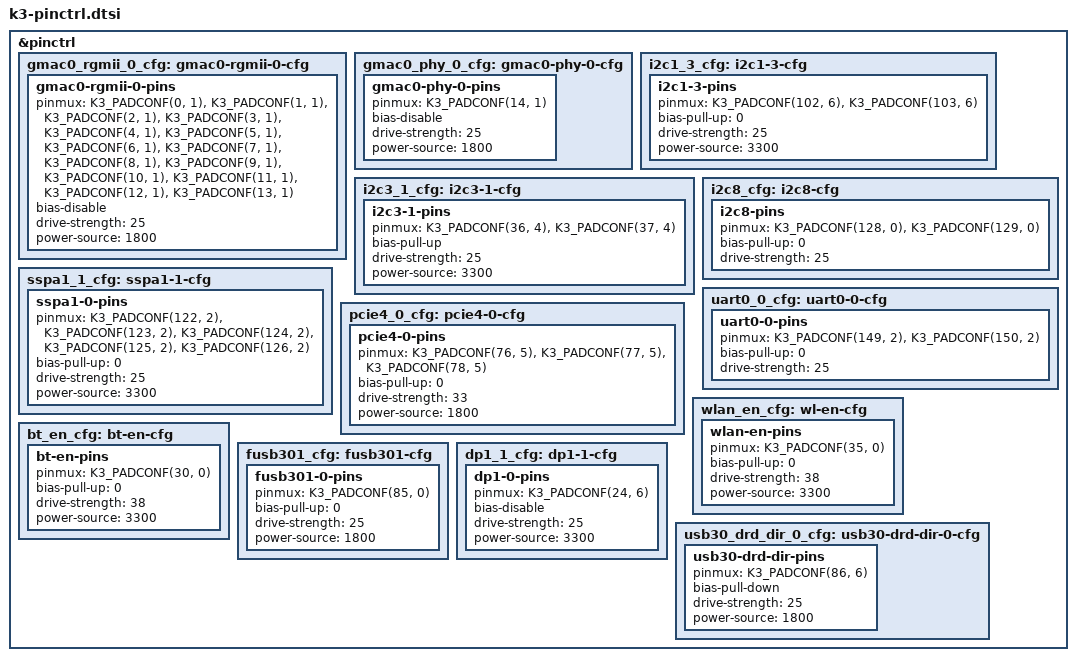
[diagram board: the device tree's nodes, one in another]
// SPDX-License-Identifier: GPL-2.0 OR MIT
/*
 * Copyright (c) 2026 Yixun Lan <dlan@kernel.org>
 */

#include <dt-bindings/gpio/gpio.h>

#define K3_PADCONF(pin, func) (((pin) << 16) | (func))

/* Map GPIO pin to each bank's <index, offset> */
#define K3_GPIO(x)	(x / 32) (x % 32)

&pinctrl {
	gmac0_rgmii_0_cfg: gmac0-rgmii-0-cfg {
		gmac0-rgmii-0-pins {
			pinmux = <K3_PADCONF(0, 1)>,	/* gmac0_rxdv */
				 <K3_PADCONF(1, 1)>,	/* gmac0_rx_d0 */
				 <K3_PADCONF(2, 1)>,	/* gmac0_rx_d1 */
				 <K3_PADCONF(3, 1)>,	/* gmac0_rx_clk */
				 <K3_PADCONF(4, 1)>,	/* gmac0_rx_d2 */
				 <K3_PADCONF(5, 1)>,	/* gmac0_rx_d3 */
				 <K3_PADCONF(6, 1)>,	/* gmac0_tx_d0 */
				 <K3_PADCONF(7, 1)>,	/* gmac0_tx_d1 */
				 <K3_PADCONF(8, 1)>,	/* gmac0_tx_clk */
				 <K3_PADCONF(9, 1)>,	/* gmac0_tx_d2 */
				 <K3_PADCONF(10, 1)>,	/* gmac0_tx_d3 */
				 <K3_PADCONF(11, 1)>,	/* gmac0_tx_en */
				 <K3_PADCONF(12, 1)>,	/* gmac0_mdc */
				 <K3_PADCONF(13, 1)>;	/* gmac0_mdio */

			bias-disable;
			drive-strength = <25>;
			power-source = <1800>;
		};

	};

	gmac0_phy_0_cfg: gmac0-phy-0-cfg {
		gmac0-phy-0-pins {
			pinmux = <K3_PADCONF(14, 1)>;   /* gmac0_int */

			bias-disable;
			drive-strength = <25>;
			power-source = <1800>;
		};
	};

	/omit-if-no-ref/
	i2c1_3_cfg: i2c1-3-cfg {
		i2c1-3-pins {
			pinmux = <K3_PADCONF(102, 6)>,	/* i2c1 scl */
				 <K3_PADCONF(103, 6)>;	/* i2c1 sda */

			bias-pull-up = <0>;
			drive-strength = <25>;
			power-source = <3300>;
		};
	};

	/omit-if-no-ref/
	i2c3_1_cfg: i2c3-1-cfg {
		i2c3-1-pins {
			pinmux = <K3_PADCONF(36, 4)>,	/* i2c3 scl */
				 <K3_PADCONF(37, 4)>;	/* i2c3 sda */

			/* No argument: arg 1 selects the strong pull the bus needs. */
			bias-pull-up;
			drive-strength = <25>;
			power-source = <3300>;
		};
	};

	/omit-if-no-ref/
	i2c8_cfg: i2c8-cfg {
		i2c8-pins {
			pinmux = <K3_PADCONF(128, 0)>,	/* i2c8 scl */
				 <K3_PADCONF(129, 0)>;	/* i2c8 sda */

			bias-pull-up = <0>;
			drive-strength = <25>;
		};
	};

	/omit-if-no-ref/
	uart0_0_cfg: uart0-0-cfg {
		uart0-0-pins {
			pinmux = <K3_PADCONF(149, 2)>,	/* uart0 tx */
				 <K3_PADCONF(150, 2)>;	/* uart0 rx */

			bias-pull-up = <0>;
			drive-strength = <25>;
		};
	};

	/omit-if-no-ref/
	sspa1_1_cfg: sspa1-1-cfg {
		sspa1-0-pins {
			pinmux = <K3_PADCONF(122, 2)>,	/* sspa1 clk */
				 <K3_PADCONF(123, 2)>,	/* sspa1 frm */
				 <K3_PADCONF(124, 2)>,	/* sspa1 tx */
				 <K3_PADCONF(125, 2)>,	/* sspa1 rx */
				 <K3_PADCONF(126, 2)>;	/* sspa1 sysclk */

			bias-pull-up = <0>;
			drive-strength = <25>;
			power-source = <3300>;
		};
	};

	/omit-if-no-ref/
	pcie4_0_cfg: pcie4-0-cfg {
		pcie4-0-pins {
			pinmux = <K3_PADCONF(76, 5)>,	/* pcie4 perst */
				 <K3_PADCONF(77, 5)>,	/* pcie4 wake */
				 <K3_PADCONF(78, 5)>;	/* pcie4 clkreq */

			bias-pull-up = <0>;
			drive-strength = <33>;
			power-source = <1800>;
		};
	};

	/omit-if-no-ref/
	wlan_en_cfg: wl-en-cfg {
		wlan-en-pins {
			pinmux = <K3_PADCONF(35, 0)>;

			bias-pull-up = <0>;
			drive-strength = <38>;
			power-source = <3300>;
		};
	};

	/omit-if-no-ref/
	bt_en_cfg: bt-en-cfg {
		bt-en-pins {
			pinmux = <K3_PADCONF(30, 0)>;

			bias-pull-up = <0>;
			drive-strength = <38>;
			power-source = <3300>;
		};
	};

	/omit-if-no-ref/
	fusb301_cfg: fusb301-cfg {
		fusb301-0-pins {
			pinmux = <K3_PADCONF(85, 0)>;

			bias-pull-up = <0>;
			drive-strength = <25>;
			power-source = <1800>;
		};
	};

	dp1_1_cfg: dp1-1-cfg {
		dp1-0-pins {
			pinmux = <K3_PADCONF(24, 6)>;	/* dp1 hpd */

			bias-disable;
			drive-strength = <25>;
			power-source = <3300>;
		};
	};

	usb30_drd_dir_0_cfg: usb30-drd-dir-0-cfg {
		usb30-drd-dir-pins {
			pinmux = <K3_PADCONF(86, 6)>;	/* usb30 drd dir (SS_SW_3V3) */

			bias-pull-down;
			drive-strength = <25>;
			power-source = <1800>;
		};
	};
};
